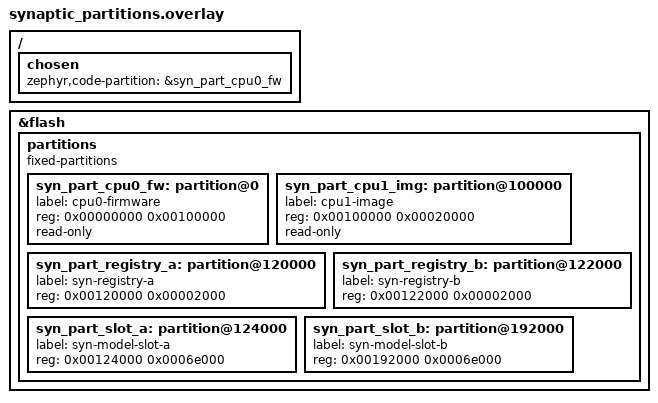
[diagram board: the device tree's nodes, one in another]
/* SPDX-License-Identifier: Apache-2.0 */
/*
 * GENERATED by tools/syn_flash_layout.py - do not edit; edit the tool and regenerate.
 *
 * SynapticOS flash partitions for frdm_mcxn947/mcxn947/cpu0.
 * Replaces the stock MCUboot-oriented partitions: the stock
 * slot1_partition (0x00108000, 992 KB) straddles CPU1's XIP bank
 * and must not exist in SynapticOS builds. Must match
 * src/core/syn_flash_map.h (BUILD_ASSERTed there).
 */

/delete-node/ &boot_partition;
/delete-node/ &slot0_partition;
/delete-node/ &slot1_partition;

/ {
	chosen {
		zephyr,code-partition = &syn_part_cpu0_fw;
	};
};

&flash {
	partitions {
		compatible = "fixed-partitions";
		#address-cells = <1>;
		#size-cells = <1>;

		syn_part_cpu0_fw: partition@0 {
			label = "cpu0-firmware";
			reg = <0x00000000 0x00100000>;
			read-only;
		};

		syn_part_cpu1_img: partition@100000 {
			label = "cpu1-image";
			reg = <0x00100000 0x00020000>;
			read-only;
		};

		syn_part_registry_a: partition@120000 {
			label = "syn-registry-a";
			reg = <0x00120000 0x00002000>;
		};

		syn_part_registry_b: partition@122000 {
			label = "syn-registry-b";
			reg = <0x00122000 0x00002000>;
		};

		syn_part_slot_a: partition@124000 {
			label = "syn-model-slot-a";
			reg = <0x00124000 0x0006e000>;
		};

		syn_part_slot_b: partition@192000 {
			label = "syn-model-slot-b";
			reg = <0x00192000 0x0006e000>;
		};
	};
};
